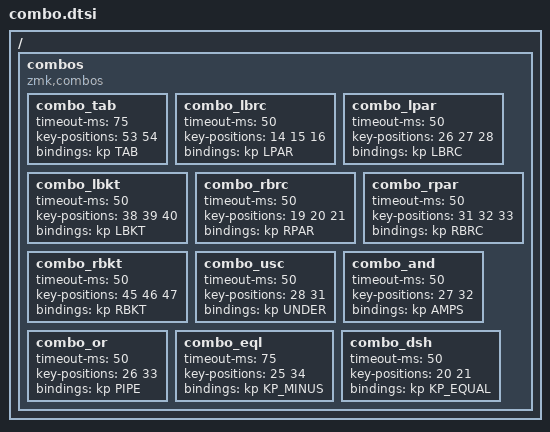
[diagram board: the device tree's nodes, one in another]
/*                                      58 KEY MATRIX / LAYOUT MAPPING

  ╭────────────────────────────┬────────────────────────────╮ 
  │  0   1   2   3   4   5     │      6   7   8   9  10  11 │
  │ 12  13  14  15  16  17     │     18  19  20  21  22  23 │
  │ 24  25  26  27  28  29     │     30  31  32  33  34  35 │
  │ 36  37  38  39  40  41  42 │ 43  44  45  46  47  48  49 │
  ╰───────────╮ 50  51  52  53 │ 54  55  56  57 ╭───────────╯
              ╰────────────────┴────────────────╯            
*/

/ {
  combos {
    compatible = "zmk,combos";

    combo_tab {
      timeout-ms = <75>;
      key-positions = <53 54>; // SPC BSPC
      bindings = <&kp TAB>;
    };

    combo_lbrc {
      timeout-ms = <50>;
      key-positions = <14 15 16>; // WER
      bindings = <&kp LPAR>;
    };

    combo_lpar {
      timeout-ms = <50>;
      key-positions = <26 27 28>; // SDF
      bindings = <&kp LBRC>;
    };

    combo_lbkt {
      timeout-ms = <50>;
      key-positions = <38 39 40>; // XCV
      bindings = <&kp LBKT>;
    };

    combo_rbrc {
      timeout-ms = <50>;
      key-positions = <19 20 21>; // UIO
      bindings = <&kp RPAR>;
    };

    combo_rpar {
      timeout-ms = <50>;
      key-positions = <31 32 33>; // JKL
      bindings = <&kp RBRC>;
    };

    combo_rbkt {
      timeout-ms = <50>;
      key-positions = <45 46 47>; // M,.
      bindings = <&kp RBKT>;
    };

    combo_usc {
      timeout-ms = <50>;
      key-positions = <28 31>; // FJ
      bindings = <&kp UNDER>;
    };

    combo_and {
      timeout-ms = <50>;
      key-positions = <27 32>; // DK
      bindings = <&kp AMPS>;
    };

    combo_or {
      timeout-ms = <50>;
      key-positions = <26 33>; // SL
      bindings = <&kp PIPE>;
    };

    combo_eql {
      timeout-ms = <75>;
      key-positions = <25 34>; // A;
      bindings = <&kp KP_MINUS>;
    };

    combo_dsh {
      timeout-ms = <50>;
      key-positions = <20 21>; // IO
      bindings = <&kp KP_EQUAL>;
    };
  };
};
